# PIC16LF1613 register map
Vendor: Microchip
Registers are 8-bit, read-write, reset 0x0 unless marked. A register's access mark holds for its fields unless they carry their own. Addresses are absolute, and some are shared; only a register's first bit layout is shown; [hi:lo] are bit positions; {n}, {i} and the like mark numbered series.

## CONFIG — Configuration words, addresses in ProgramSpace
0x8007 CONFIG1 14-bit reset 0x3FFF
  [11] CLKOUTEN — Clock Out Enable
    1=OFF (CLKOUT function is disabled. I/O or oscillator function on the CLKOUT pin); 0=ON (CLKOUT function is enabled on the CLKOUT pin)
  [10:9] BOREN — Brown-out Reset Enable
    3=ON (Brown-out Reset enabled); 2=NSLEEP (Brown-out Reset enabled while running and disabled in Sleep); 1=SBODEN (Brown-out Reset controlled by the SBOREN bit in the BORCON register); 0=OFF (Brown-out Reset disabled)
  [7] CP — Flash Program Memory Code Protection
    1=OFF (Program memory code protection is disabled); 0=ON (Program memory code protection is enabled)
  [6] MCLRE — MCLR Pin Function Select
    1=ON (MCLR/VPP pin function is MCLR); 0=OFF (MCLR/VPP pin function is digital input)
  [5] PWRTE — Power-up Timer Enable
    1=OFF (PWRT disabled); 0=ON (PWRT enabled)
  [1:0] FOSC — Oscillator Selection Bits
    3=ECH (ECH, External Clock, High Power Mode (4-32 MHz): device clock supplied to CLKIN pins); 2=ECM (ECM, External Clock, Medium Power Mode (0.5-4 MHz): device clock supplied to CLKIN pins); 1=ECL (ECL, External Clock, Low Power Mode (0-0.5 MHz): device clock supplied to CLKIN pins); 0=INTOSC (INTOSC oscillator: I/O function on CLKIN pin)
0x8008 CONFIG2 14-bit reset 0x3FFF
  [13] LVP — Low-Voltage Programming Enable
    1=ON (Low-voltage programming enabled); 0=OFF (High-voltage on MCLR/VPP must be used for programming)
  [12] DEBUG — In-Circuit Debugger Mode
    1=OFF (In-Circuit Debugger disabled, ICSPCLK and ICSPDAT are general purpose I/O pins); 0=ON (In-Circuit Debugger enabled, ICSPCLK and ICSPDAT are dedicated to the debugger)
  [11] LPBOR — Low-Power Brown Out Reset
    1=OFF (Low-Power BOR is disabled); 0=ON (Low-Power BOR is enabled)
  [10] BORV — Brown-out Reset Voltage Selection
    1=LO (Brown-out Reset Voltage (Vbor), low trip point selected.); 0=HI (Brown-out Reset Voltage (Vbor), high trip point selected.)
  [9] STVREN — Stack Overflow/Underflow Reset Enable
    1=ON (Stack Overflow or Underflow will cause a Reset); 0=OFF (Stack Overflow or Underflow will not cause a Reset)
  [8] PLLEN — PLL Enable Bit
    1=ON (4x PLL is always enabled); 0=OFF (4x PLL is enabled when software sets the SPLLEN bit)
  [7] ZCD — Zero Cross Detect Disable Bit
    1=OFF (ZCD disable. ZCD can be enabled by setting the ZCDSEN bit of ZCDCON); 0=ON (ZCD always enabled)
  [1:0] WRT — Flash Memory Self-Write Protection
    3=OFF (Write protection off); 2=BOOT (000h to 1FFh write protected, 200h to 1FFFh may be modified by PMCON control); 1=HALF (000h to FFFh write protected, 1000h to 1FFFh may be modified by PMCON control); 0=ALL (000h to 1FFFh write protected, no addresses may be modified by EECON control)
0x8009 CONFIG3 14-bit reset 0x3FFF
  [13:11] WDTCCS — WDT Input Clock Selector
    0=LFINTOSC (31.0 kHz LFINTOSC); 1=MFINTOSC (31.25 kHz HFINTOSC (MFINTOSC)); 7=SWC (Software control, controlled by WDTCS bits)
  [10:8] WDTCWS — WDT Window Select
    0=12.5 percent window open time; 1=25 percent window open time; 2=37.5 percent window open time; 3=50 percent window open time; 4=62.5 percent window open time; 5=75 percent window open time; 6=100 percent window open time (Legacy WDT); 7=WDTCWSSW (Software WDT window size control (WDTWS bits))
  [6:5] WDTE — Watchdog Timer Enable
    3=ON (WDT enabled); 2=NSLEEP (WDT enabled while running and disabled in Sleep); 1=SWDTEN (WDT controlled by the SWDTEN bit in the WDTCON register); 0=OFF (WDT disabled)
  [4:0] WDTCPS — WDT Period Select
    0=1:32 (1 ms period); 1=1:64 (2 ms period); 2=1:128 (4 ms period); 3=1:256 (8 ms period); 4=1:512 (16 ms period); 5=1:1024 (32 ms period); 6=1:2048 (64 ms period); 7=1:4096 (128 ms period); 8=1:8192 (256 ms period); 9=1:16384 (512 ms period); 10=WDTCPSA (1:32768 (1 s period)); 11=WDTCPSB (1:65536 (2 s period)); 12=WDTCPSC (1:131072 (4 s period)); 13=WDTCPSD (1:262144 (8 s period)); 14=WDTCPSE (1:524299 (16 s period)); 15=WDTCPSF (1:1048576 (32 s period)); 16=1:2097152 (64 s period); 17=1:4194304 (128 s period); 18=1:8388608 (256 s period); 31=WDTCPS1F (Software Control (WDTPS))

## math_progcrc
0x791 CRCDATL reset not defined — (power-on value xxxxxxxx)
  [7:0] DAT
0x792 CRCDATH reset not defined — (power-on value xxxxxxxx)
  [7:0] DAT
0x793 CRCACCL
  [7:0] ACC
0x794 CRCACCH
  [7:0] ACC
0x795 CRCSHIFTL
  [7:0] SHIFT
0x796 CRCSHIFTH
  [7:0] SHIFT
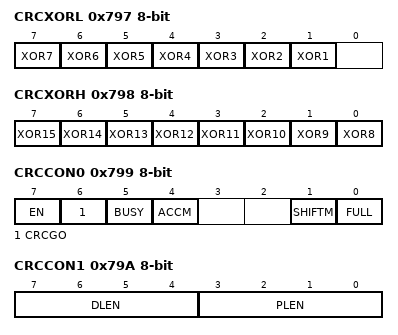
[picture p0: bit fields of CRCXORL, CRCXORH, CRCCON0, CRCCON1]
0x797 CRCXORL reset not defined — (power-on value xxxxxxx-)
  [n] XOR{n} (n=1..7)
0x798 CRCXORH reset not defined — (power-on value xxxxxxxx)
  [n-8] XOR{n} (n=8..15)
0x799 CRCCON0
  [7] EN, [6] CRCGO, [5] BUSY ro, [4] ACCM, [1] SHIFTM, [0] FULL ro
0x79A CRCCON1
  [7:4] DLEN, [3:0] PLEN

## tmr_smt
0xD8C SMT1TMRL
  [7:0] SMT1TMR
0xD8D SMT1TMRH
  [7:0] SMT1TMR
0xD8E SMT1TMRU
  [7:0] SMT1TMR
0xD8F SMT1CPRL ro reset not defined — (power-on value xxxxxxxx)
  [7:0] SMT1CPR
0xD90 SMT1CPRH ro reset not defined — (power-on value xxxxxxxx)
  [7:0] SMT1CPR
0xD91 SMT1CPRU ro reset not defined — (power-on value xxxxxxxx)
  [7:0] SMT1CPR
0xD92 SMT1CPWL ro reset not defined — (power-on value xxxxxxxx)
  [7:0] SMT1CPW
0xD93 SMT1CPWH ro reset not defined — (power-on value xxxxxxxx)
  [7:0] SMT1CPW
0xD94 SMT1CPWU ro reset not defined — (power-on value xxxxxxxx)
  [7:0] SMT1CPW
0xD95 SMT1PRL reset 0xFF
  [7:0] SMT1PR
0xD96 SMT1PRH reset 0xFF
  [7:0] SMT1PR
0xD97 SMT1PRU reset 0xFF
  [7:0] SMT1PR
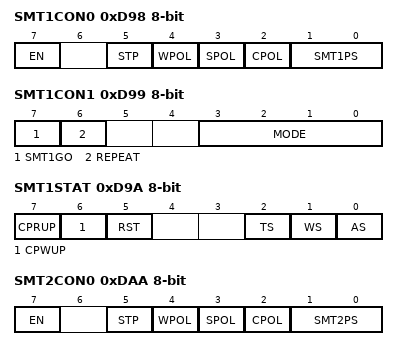
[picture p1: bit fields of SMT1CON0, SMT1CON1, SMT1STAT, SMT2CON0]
0xD98 SMT1CON0
  [7] EN, [5] STP, [4] WPOL, [3] SPOL, [2] CPOL, [1:0] SMT1PS
0xD99 SMT1CON1
  [7] SMT1GO, [6] REPEAT, [3:0] MODE
0xD9A SMT1STAT
  [7] CPRUP, [6] CPWUP, [5] RST, [2] TS ro, [1] WS ro, [0] AS ro
0xD9B SMT1CLK
  [2:0] CSEL
0xD9C SMT1SIG
  [2:0] SSEL
0xD9D SMT1WIN
  [3:0] WSEL
0xD9E SMT2TMRL
  [7:0] SMT2TMR
0xD9F SMT2TMRH
  [7:0] SMT2TMR
0xDA0 SMT2TMRU
  [7:0] SMT2TMR
0xDA1 SMT2CPRL ro reset not defined — (power-on value xxxxxxxx)
  [7:0] SMT2CPR
0xDA2 SMT2CPRH ro reset not defined — (power-on value xxxxxxxx)
  [7:0] SMT2CPR
0xDA3 SMT2CPRU ro reset not defined — (power-on value xxxxxxxx)
  [7:0] SMT2CPR
0xDA4 SMT2CPWL ro reset not defined — (power-on value xxxxxxxx)
  [7:0] SMT2CPW
0xDA5 SMT2CPWH ro reset not defined — (power-on value xxxxxxxx)
  [7:0] SMT2CPW
0xDA6 SMT2CPWU ro reset not defined — (power-on value xxxxxxxx)
  [7:0] SMT2CPW
0xDA7 SMT2PRL reset 0xFF
  [7:0] SMT2PR
0xDA8 SMT2PRH reset 0xFF
  [7:0] SMT2PR
0xDA9 SMT2PRU reset 0xFF
  [7:0] SMT2PR
0xDAA SMT2CON0
  [7] EN, [5] STP, [4] WPOL, [3] SPOL, [2] CPOL, [1:0] SMT2PS
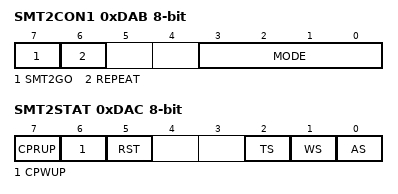
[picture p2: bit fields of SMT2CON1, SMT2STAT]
0xDAB SMT2CON1
  [7] SMT2GO, [6] REPEAT, [3:0] MODE
0xDAC SMT2STAT
  [7] CPRUP, [6] CPWUP, [5] RST, [2] TS ro, [1] WS ro, [0] AS ro
0xDAD SMT2CLK
  [2:0] CSEL
0xDAE SMT2SIG
  [2:0] SSEL
0xDAF SMT2WIN
  [3:0] WSEL
